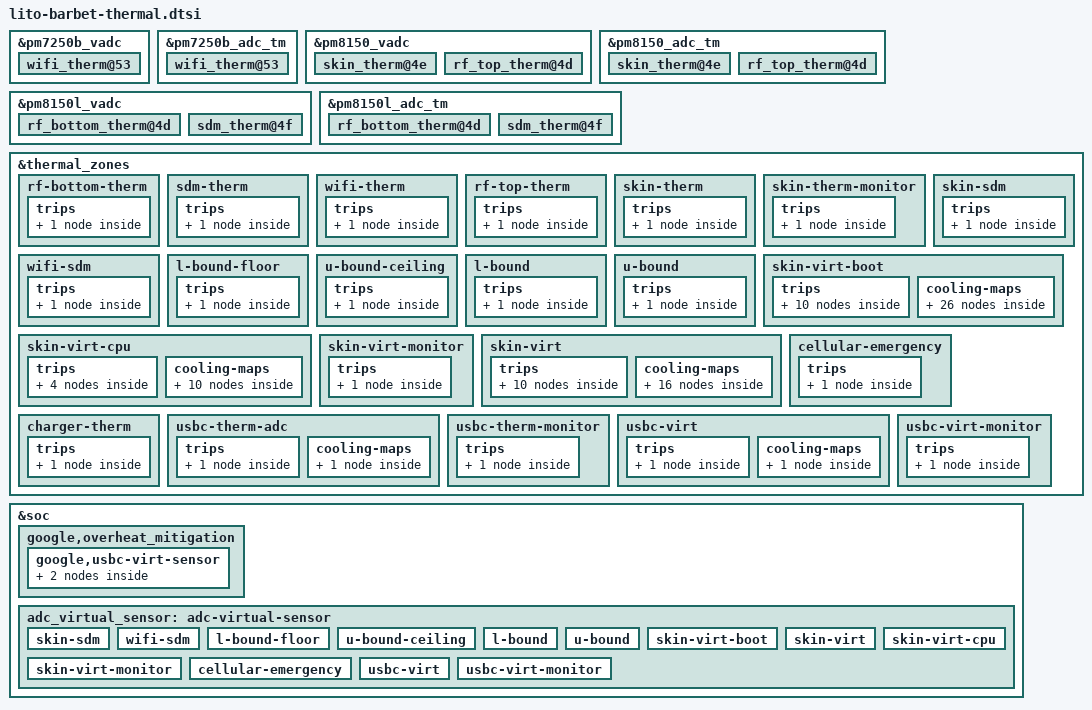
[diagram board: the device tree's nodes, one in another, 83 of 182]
// SPDX-License-Identifier: GPL-2.0
/* Copyright (c) 2019, The Linux Foundation. All rights reserved.
 *
 * This program is free software; you can redistribute it and/or modify
 * it under the terms of the GNU General Public License version 2 and
 * only version 2 as published by the Free Software Foundation.
 *
 * This program is distributed in the hope that it will be useful,
 * but WITHOUT ANY WARRANTY; without even the implied warranty of
 * MERCHANTABILITY or FITNESS FOR A PARTICULAR PURPOSE.  See the
 * GNU General Public License for more details.
 */

&pm7250b_vadc {
	wifi_therm@53 {
		reg = <ADC_GPIO2_PU2>;
		label = "wifi_therm";
		qcom,ratiometric;
		qcom,hw-settle-time = <200>;
		qcom,pre-scaling = <1 1>;
	};
};

&pm7250b_adc_tm {
	io-channels = <&pm7250b_vadc ADC_AMUX_THM1_PU2>,
			<&pm7250b_vadc ADC_AMUX_THM3_PU2>,
			<&pm7250b_vadc ADC_GPIO2_PU2>;

	wifi_therm@53 {
		reg = <ADC_GPIO2_PU2>;
		qcom,ratiometric;
		qcom,hw-settle-time = <200>;
	};
};

&pm8150_vadc {
	skin_therm@4e {
		reg = <ADC_AMUX_THM2_PU2>;
		label = "skin_therm";
		qcom,ratiometric;
		qcom,hw-settle-time = <200>;
		qcom,pre-scaling = <1 1>;
	};

	rf_top_therm@4d {
		reg = <ADC_AMUX_THM1_PU2>;
		label = "rf_top_therm";
		qcom,ratiometric;
		qcom,hw-settle-time = <200>;
		qcom,pre-scaling = <1 1>;
	};
};

&pm8150_adc_tm {
	io-channels = <&pm8150_vadc ADC_XO_THERM_PU2>,
			<&pm8150_vadc ADC_AMUX_THM1_PU2>,
			<&pm8150_vadc ADC_AMUX_THM2_PU2>;

	skin_therm@4e {
		reg = <ADC_AMUX_THM2_PU2>;
		qcom,ratiometric;
		qcom,hw-settle-time = <200>;
	};

	rf_top_therm@4d {
		reg = <ADC_AMUX_THM1_PU2>;
		qcom,ratiometric;
		qcom,hw-settle-time = <200>;
	};
};

&pm8150l_vadc {

	rf_bottom_therm@4d {
		reg = <ADC_AMUX_THM1_PU2>;
		label = "rf_bottom_therm";
		qcom,ratiometric;
		qcom,hw-settle-time = <200>;
		qcom,pre-scaling = <1 1>;
	};

	sdm_therm@4f {
		reg = <ADC_AMUX_THM3_PU2>;
		label = "sdm_therm";
		qcom,ratiometric;
		qcom,hw-settle-time = <200>;
		qcom,pre-scaling = <1 1>;
	};
};

&pm8150l_adc_tm {
	io-channels = <&pm8150l_vadc ADC_AMUX_THM1_PU2>,
			<&pm8150l_vadc ADC_AMUX_THM3_PU2>;

	/* Channel nodes */
	rf_bottom_therm@4d {
		reg = <ADC_AMUX_THM1_PU2>;
		qcom,ratiometric;
		qcom,hw-settle-time = <200>;
	};

	sdm_therm@4f {
		reg = <ADC_AMUX_THM3_PU2>;
		qcom,ratiometric;
		qcom,hw-settle-time = <200>;
	};
};

&thermal_zones {
	rf-bottom-therm {
		polling-delay-passive = <0>;
		polling-delay = <0>;
		thermal-governor = "user_space";
		thermal-sensors = <&pm8150l_adc_tm ADC_AMUX_THM1_PU2>;
		wake-capable-sensor;
		trips {
			active-config0 {
				temperature = <125000>;
				hysteresis = <1000>;
				type = "passive";
			};
		};
	};

	sdm-therm {
		polling-delay-passive = <0>;
		polling-delay = <0>;
		thermal-governor = "user_space";
		thermal-sensors = <&pm8150l_adc_tm ADC_AMUX_THM3_PU2>;
		wake-capable-sensor;
		trips {
			active-config0 {
				temperature = <125000>;
				hysteresis = <1000>;
				type = "passive";
			};
		};
	};

	wifi-therm {
		polling-delay-passive = <0>;
		polling-delay = <0>;
		thermal-governor = "user_space";
		thermal-sensors = <&pm7250b_adc_tm ADC_GPIO2_PU2>;
		wake-capable-sensor;
		trips {
			active-config0 {
				temperature = <125000>;
				hysteresis = <1000>;
				type = "passive";
			};
		};
	};

	rf-top-therm {
		polling-delay-passive = <0>;
		polling-delay = <0>;
		thermal-governor = "user_space";
		thermal-sensors = <&pm8150_adc_tm ADC_AMUX_THM1_PU2>;
		wake-capable-sensor;
		trips {
			active-config0 {
				temperature = <125000>;
				hysteresis = <1000>;
				type = "passive";
			};
		};
	};

	skin-therm {
		polling-delay-passive = <0>;
		polling-delay = <0>;
		thermal-governor = "user_space";
		thermal-sensors = <&pm8150_adc_tm ADC_AMUX_THM2_PU2>;
		wake-capable-sensor;
		trips {
			active-config0 {
				temperature = <125000>;
				hysteresis = <1000>;
				type = "passive";
			};
		};
	};

	skin-therm-monitor {
		polling-delay-passive = <0>;
		polling-delay = <0>;
		thermal-governor = "user_space";
		thermal-sensors = <&pm8150_adc_tm ADC_AMUX_THM2_PU2>;
		wake-capable-sensor;
		trips {
			active-config0 {
				temperature = <125000>;
				hysteresis = <1000>;
				type = "passive";
			};
		};
	};

	skin-sdm {
		polling-delay-passive = <0>;
		polling-delay = <0>;
		thermal-governor = "user_space";
		disable-thermal-zone;
		trips {
			active-config0 {
				temperature = <125000>;
				hysteresis = <1000>;
				type = "passive";
			};
		};
	};

	wifi-sdm {
		polling-delay-passive = <0>;
		polling-delay = <0>;
		thermal-governor = "user_space";
		disable-thermal-zone;
		trips {
			active-config0 {
				temperature = <125000>;
				hysteresis = <1000>;
				type = "passive";
			};
		};
	};

	l-bound-floor {
		polling-delay-passive = <0>;
		polling-delay = <0>;
		thermal-governor = "user_space";
		disable-thermal-zone;
		trips {
			active-config0 {
				temperature = <125000>;
				hysteresis = <1000>;
				type = "passive";
			};
		};
	};

	u-bound-ceiling {
		polling-delay-passive = <0>;
		polling-delay = <0>;
		thermal-governor = "user_space";
		disable-thermal-zone;
		trips {
			active-config0 {
				temperature = <125000>;
				hysteresis = <1000>;
				type = "passive";
			};
		};
	};

	l-bound {
		polling-delay-passive = <0>;
		polling-delay = <0>;
		thermal-governor = "user_space";
		disable-thermal-zone;
		trips {
			active-config0 {
				temperature = <125000>;
				hysteresis = <1000>;
				type = "passive";
			};
		};
	};

	u-bound {
		polling-delay-passive = <0>;
		polling-delay = <0>;
		thermal-governor = "user_space";
		disable-thermal-zone;
		trips {
			active-config0 {
				temperature = <125000>;
				hysteresis = <1000>;
				type = "passive";
			};
		};
	};

	skin-virt-boot {
		polling-delay-passive = <5000>;
		polling-delay = <5000>;
		thermal-governor = "step_wise";
		trips {
			boot_light_pre_lv1: boot-light-pre-lv1 {
				temperature = <41000>;
				hysteresis = <1000>;
				type = "passive";
			};
			boot_light_pre_lv2: boot-light-pre-lv2 {
				temperature = <42000>;
				hysteresis = <1000>;
				type = "passive";
			};
			boot_light: boot-light {
				temperature = <43000>;
				hysteresis = <1000>;
				type = "passive";
			};
			boot_moderate_pre_lv1: boot-moderate-pre-lv1 {
				temperature = <44000>;
				hysteresis = <1000>;
				type = "passive";
			};
			boot_moderate: boot-moderate {
				temperature = <45000>;
				hysteresis = <1000>;
				type = "passive";
			};
			boot_severe_pre_lv1: boot-severe-pre-lv1 {
				temperature = <46000>;
				hysteresis = <1000>;
				type = "passive";
			};
			boot_severe: boot-severe {
				temperature = <47000>;
				hysteresis = <1000>;
				type = "passive";
			};
			boot_critical: boot-critical {
				temperature = <49000>;
				hysteresis = <1000>;
				type = "passive";
			};
			boot_emergency_pre_lv1: boot-emerency-pre-lv1 {
				temperature = <51000>;
				hysteresis = <1000>;
				type = "passive";
			};
			boot_backup_shutdown: boot-backup-shutdown {
				temperature = <59000>;
				hysteresis = <1000>;
				type = "critical";
			};
		};
		cooling-maps {
			/* light pre level 1 throttling */
			wired-charge-pd-5v {
				trip = <&boot_light_pre_lv1>;
				cooling-device = <&google_charger_pd_5v
					THERMAL_MAX_LIMIT THERMAL_MAX_LIMIT>;
			};
			wired-charge-ibat-3000mA {
				trip = <&boot_light_pre_lv1>;
				cooling-device =
					<&google_charger 2 2>;
			};
			/* light pre level 2 throttling */
			wired-charge-ibat-2500mA {
				trip = <&boot_light_pre_lv2>;
				cooling-device =
					<&google_charger 3 3>;
			};
			/* light throttling */
			wired-charge-ibat-2000mA {
				trip = <&boot_light>;
				cooling-device =
					<&google_charger 4 4>;
			};
			cpu6-turbo {
				trip = <&boot_light>;
				cooling-device =
					<&CPU6 1 2>;
			};
			cpu7-turbo {
				trip = <&boot_light>;
				cooling-device =
					<&CPU7 1 1>;
			};
			/* moderate pre level 1 throttling */
			wired-charge-ibat-1500mA {
				trip = <&boot_moderate_pre_lv1>;
				cooling-device =
					<&google_charger 5 5>;
			};
			cpu6-nominal-l1 {
				trip = <&boot_moderate_pre_lv1>;
				cooling-device =
					<&CPU6 3 3>;
			};
			cpu7-nominal-l1 {
				trip = <&boot_moderate_pre_lv1>;
				cooling-device =
					<&CPU7 2 3>;
			};
			/* moderate throttling */
			wired-charge-ibat-1000mA {
				trip = <&boot_moderate>;
				cooling-device =
					<&google_charger 6 6>;
			};
			cpu0-nominal {
				trip = <&boot_moderate>;
				cooling-device =
					<&CPU0 1 3>;
			};
			cpu6-nominal {
				trip = <&boot_moderate>;
				cooling-device =
					<&CPU6 4 4>;
			};
			cpu7-nominal {
				trip = <&boot_moderate>;
				cooling-device =
					<&CPU7 4 4>;
			};
			/* severe pre level 1 throttling */
			wired-charge-ibat-500mA {
				trip = <&boot_severe_pre_lv1>;
				cooling-device =
					<&google_charger 7 7>;
			};
			/* severe throttling */
			wired-charge-disabled {
				trip = <&boot_severe>;
				cooling-device = <&google_charger
					THERMAL_MAX_LIMIT THERMAL_MAX_LIMIT>;
			};
			cpu0-svs-l1 {
				trip = <&boot_severe>;
				cooling-device =
					<&CPU0 4 4>;
			};
			cpu6-svs-l1 {
				trip = <&boot_severe>;
				cooling-device =
					<&CPU6 5 5>;
			};
			cpu7-svs-l1 {
				trip = <&boot_severe>;
				cooling-device =
					<&CPU7 5 5>;
			};
			/* critical throttling */
			gpu-svs-l1 {
				trip = <&boot_critical>;
				cooling-device = <&msm_gpu 1 1>;
			};
			cpu0-svs {
				trip = <&boot_critical>;
				cooling-device =
					<&CPU0 5 5>;
			};
			cpu6-svs {
				trip = <&boot_critical>;
				cooling-device =
					<&CPU6 6 6>;
			};
			cpu7-svs {
				trip = <&boot_critical>;
				cooling-device =
					<&CPU7 6 6>;
			};
			/* emergency pre level 1 throttling */
			gpu-svs {
				trip = <&boot_emergency_pre_lv1>;
				cooling-device =
					<&msm_gpu 2 2>;
			};
			cpu0-low-svs {
				trip = <&boot_emergency_pre_lv1>;
				cooling-device =
					<&CPU0 6 6>;
			};
			cpu6-low-svs {
				trip = <&boot_emergency_pre_lv1>;
				cooling-device =
					<&CPU6 7 7>;
			};
			cpu7-low-svs {
				trip = <&boot_emergency_pre_lv1>;
				cooling-device =
					<&CPU7 7 7>;
			};
		};
	};

	skin-virt-cpu {
		polling-delay-passive = <5000>;
		polling-delay = <10000>;
		thermal-governor = "step_wise";
		disable-thermal-zone;
		trips {
			skin_cpu_light: skin-cpu-light {
				temperature = <43000>;
				hysteresis = <1000>;
				type = "passive";
			};
			skin_cpu_moderate_pre_lv1: skin-cpu-moderate-pre-lv1 {
				temperature = <44000>;
				hysteresis = <1000>;
				type = "passive";
			};
			skin_cpu_moderate: skin-cpu-moderate {
				temperature = <45000>;
				hysteresis = <1000>;
				type = "passive";
			};
			skin_cpu_severe: skin-cpu-severe {
				temperature = <47000>;
				hysteresis = <1000>;
				type = "passive";
			};
		};
		cooling-maps {
			/* light throttling */
			cpu6-turbo {
				trip = <&skin_cpu_light>;
				cooling-device =
					<&CPU6 1 2>;
			};
			cpu7-turbo {
				trip = <&skin_cpu_light>;
				cooling-device =
					<&CPU7 1 1>;
			};
			/* moderate pre level 1 throttling */
			cpu6-nominal-l1 {
				trip = <&skin_cpu_moderate_pre_lv1>;
				cooling-device =
					<&CPU6 3 3>;
			};
			cpu7-nominal-l1 {
				trip = <&skin_cpu_moderate_pre_lv1>;
				cooling-device =
					<&CPU7 2 3>;
			};
			/* moderate throttling */
			cpu0-nominal {
				trip = <&skin_cpu_moderate>;
				cooling-device =
					<&CPU0 1 3>;
			};
			cpu6-nominal {
				trip = <&skin_cpu_moderate>;
				cooling-device =
					<&CPU6 4 4>;
			};
			cpu7-nominal {
				trip = <&skin_cpu_moderate>;
				cooling-device =
					<&CPU7 4 4>;
			};
			/* severe throttling */
			cpu0-svs-l1 {
				trip = <&skin_cpu_severe>;
				cooling-device =
					<&CPU0 4 4>;
			};
			cpu6-svs-l1 {
				trip = <&skin_cpu_severe>;
				cooling-device =
					<&CPU6 5 5>;
			};
			cpu7-svs-l1 {
				trip = <&skin_cpu_severe>;
				cooling-device =
					<&CPU7 5 5>;
			};
		};
	};

	skin-virt-monitor {
		polling-delay-passive = <0>;
		polling-delay = <0>;
		thermal-governor = "user_space";
		trips {
			active-config0 {
				temperature = <125000>;
				hysteresis = <1000>;
				type = "passive";
			};
		};
	};

	skin-virt {
		polling-delay-passive = <5000>;
		polling-delay = <10000>;
		thermal-governor = "step_wise";
		disable-thermal-zone;
		trips {
			skin_light_pre_lv1: skin-light-pre-lv1 {
				temperature = <41000>;
				hysteresis = <1000>;
				type = "passive";
			};
			skin_light_pre_lv2: skin-light-pre-lv2 {
				temperature = <42000>;
				hysteresis = <1000>;
				type = "passive";
			};
			skin_light: skin-light {
				temperature = <43000>;
				hysteresis = <1000>;
				type = "passive";
			};
			skin_moderate_pre_lv1: skin-moderate-pre-lv1 {
				temperature = <44000>;
				hysteresis = <1000>;
				type = "passive";
			};
			skin_moderate: skin-moderate {
				temperature = <45000>;
				hysteresis = <1000>;
				type = "passive";
			};
			skin_severe_pre_lv1: skin-severe-pre-lv1 {
				temperature = <46000>;
				hysteresis = <1000>;
				type = "passive";
			};
			skin_severe: skin-severe {
				temperature = <47000>;
				hysteresis = <1000>;
				type = "passive";
			};
			skin_critical: skin-critical {
				temperature = <49000>;
				hysteresis = <1000>;
				type = "passive";
			};
			skin_emergency_pre_lv1: skin-emerency-pre-lv1 {
				temperature = <51000>;
				hysteresis = <1000>;
				type = "passive";
			};
			skin_backup_shutdown: skin-backup-shutdown {
				temperature = <59000>;
				hysteresis = <1000>;
				type = "critical";
			};
		};
		cooling-maps {
			/* light pre level 1 throttling */
			wired-charge-pd-5v {
				trip = <&skin_light_pre_lv1>;
				cooling-device = <&google_charger_pd_5v
					THERMAL_MAX_LIMIT THERMAL_MAX_LIMIT>;
			};
			wired-charge-ibat-3000mA {
				trip = <&skin_light_pre_lv1>;
				cooling-device =
					<&google_charger 2 2>;
			};
			/* light pre level 2 throttling */
			wired-charge-ibat-2500mA {
				trip = <&skin_light_pre_lv2>;
				cooling-device =
					<&google_charger 3 3>;
			};
			/* light throttling */
			wired-charge-ibat-2000mA {
				trip = <&skin_light>;
				cooling-device =
					<&google_charger 4 4>;
			};
			/* moderate pre level 1 throttling */
			wired-charge-ibat-1500mA {
				trip = <&skin_moderate_pre_lv1>;
				cooling-device =
					<&google_charger 5 5>;
			};
			/* moderate throttling */
			wired-charge-ibat-1000mA {
				trip = <&skin_moderate>;
				cooling-device =
					<&google_charger 6 6>;
			};
			/* severe pre level 1 throttling */
			wired-charge-ibat-500mA {
				trip = <&skin_severe_pre_lv1>;
				cooling-device =
					<&google_charger 7 7>;
			};
			/* severe throttling */
			wired-charge-disabled {
				trip = <&skin_severe>;
				cooling-device = <&google_charger
					THERMAL_MAX_LIMIT THERMAL_MAX_LIMIT>;
			};
			/* critical throttling */
			gpu-svs-l1 {
				trip = <&skin_critical>;
				cooling-device = <&msm_gpu 1 1>;
			};
			cpu0-svs {
				trip = <&skin_critical>;
				cooling-device =
					<&CPU0 5 5>;
			};
			cpu6-svs {
				trip = <&skin_critical>;
				cooling-device =
					<&CPU6 6 6>;
			};
			cpu7-svs {
				trip = <&skin_critical>;
				cooling-device =
					<&CPU7 6 6>;
			};
			/* emergency pre level 1 throttling */
			gpu-svs {
				trip = <&skin_emergency_pre_lv1>;
				cooling-device =
					<&msm_gpu 2 2>;
			};
			cpu0-low-svs {
				trip = <&skin_emergency_pre_lv1>;
				cooling-device =
					<&CPU0 6 6>;
			};
			cpu6-low-svs {
				trip = <&skin_emergency_pre_lv1>;
				cooling-device =
					<&CPU6 7 7>;
			};
			cpu7-low-svs {
				trip = <&skin_emergency_pre_lv1>;
				cooling-device =
					<&CPU7 7 7>;
			};
		};
	};

	cellular-emergency {
		polling-delay-passive = <0>;
		polling-delay = <0>;
		thermal-governor = "user_space";
		trips {
			active-config0 {
				temperature = <125000>;
				hysteresis = <1000>;
				type = "passive";
			};
		};
	};

	charger-therm {
		polling-delay-passive = <0>;
		polling-delay = <0>;
		thermal-governor = "user_space";
		thermal-sensors = <&pm7250b_adc_tm ADC_AMUX_THM1_PU2>;
		wake-capable-sensor;
		trips {
			active-config0 {
				temperature = <125000>;
				hysteresis = <1000>;
				type = "passive";
			};
		};
	};

	usbc-therm-adc {
		polling-delay-passive = <0>;
		polling-delay = <0>;
		thermal-governor = "step_wise";
		thermal-sensors = <&pm7250b_adc_tm ADC_AMUX_THM3_PU2>;
		wake-capable-sensor;
		trips {
			usb_throttling_lv1: usb-throttling_lv1 {
				temperature = <40000>;
				hysteresis = <1000>;
				type = "passive";
			};
		};
		cooling-maps {
			usb_throttling_lv1 {
				trip = <&usb_throttling_lv1>;
				cooling-device =
					<&google_overheat_mitigation 1 1>;
			};
		};
	};

	usbc-therm-monitor {
		polling-delay-passive = <0>;
		polling-delay = <0>;
		thermal-governor = "user_space";
		thermal-sensors = <&pm7250b_adc_tm ADC_AMUX_THM3_PU2>;
		wake-capable-sensor;
		trips {
			active-config0 {
				temperature = <125000>;
				hysteresis = <1000>;
				type = "passive";
			};
		};
	};

	usbc-virt {
		polling-delay-passive = <2000>;
		polling-delay = <2000>;
		thermal-governor = "step_wise";
		disable-thermal-zone;
		trips {
			usb_throttling_max: usb-throttling_max {
				temperature = <7000>;
				hysteresis = <4000>;
				type = "passive";
			};
		};
		cooling-maps {
			usb_throttling_max {
				trip = <&usb_throttling_max>;
				cooling-device =
					<&google_overheat_mitigation
					THERMAL_MAX_LIMIT THERMAL_MAX_LIMIT>;
			};
		};
	};

	usbc-virt-monitor {
		polling-delay-passive = <0>;
		polling-delay = <0>;
		thermal-governor = "user_space";
		disable-thermal-zone;
		trips {
			active-config0 {
				temperature = <125000>;
				hysteresis = <1000>;
				type = "passive";
			};
		};
	};
};

&soc {
	google,overheat_mitigation {
		google,begin-mitigation-temp = <400>;
		google,end-mitigation-temp = <390>;
		google,usbc-virt-sensor {
			usbc-virt {
				sensor-name = "usbc-virt";
			};

			usbc-virt-monitor {
				sensor-name = "usbc-virt-monitor";
				support_uevent;
			};
		};
	};

	adc_virtual_sensor: adc-virtual-sensor {
	};
};

&adc_virtual_sensor {
	skin-sdm {
		logic = "weight";
		num_sensors = <2>;
		sensor-names = "skin-therm", "sdm-therm";
		coefficients = <1 1>;
		avg-offset = <0>;
		avg-denominator = <2>;
	};

	wifi-sdm {
		logic = "weight";
		num_sensors = <2>;
		sensor-names = "wifi-therm", "sdm-therm";
		coefficients = <28 (-28)>;
		avg-offset = <0>;
		avg-denominator = <100>;
	};

	l-bound-floor {
		logic = "weight";
		num_sensors = <1>;
		sensor-names = "skin-sdm";
		coefficients = <1>;
		avg-offset = <0>;
		avg-denominator = <1>;
	};

	u-bound-ceiling {
		logic = "weight";
		num_sensors = <1>;
		sensor-names = "skin-sdm";
		coefficients = <1>;
		avg-offset = <0>;
		avg-denominator = <1>;
	};

	l-bound {
		logic = "maximum";
		num_sensors = <2>;
		sensor-names = "wifi-sdm", "l-bound-floor";
	};

	u-bound {
		logic = "minimum";
		num_sensors = <2>;
		sensor-names = "l-bound", "u-bound-ceiling";
	};

	skin-virt-boot {
		logic = "weight";
		num_sensors = <2>;
		sensor-names = "skin-therm", "sdm-therm";
		coefficients = <1 1>;
		avg-offset = <0>;
		avg-denominator = <2>;
	};

	skin-virt {
		logic = "weight";
		num_sensors = <2>;
		sensor-names = "skin-sdm", "u-bound";
		coefficients = <1 (-1)>;
		avg-offset = <0>;
		avg-denominator = <1>;
	};

	skin-virt-cpu {
		logic = "weight";
		num_sensors = <2>;
		sensor-names = "skin-sdm", "u-bound";
		coefficients = <1 (-1)>;
		avg-offset = <0>;
		avg-denominator = <1>;
	};

	skin-virt-monitor {
		logic = "weight";
		num_sensors = <2>;
		sensor-names = "skin-sdm", "u-bound";
		coefficients = <1 (-1)>;
		avg-offset = <0>;
		avg-denominator = <1>;
	};

	cellular-emergency {
		logic = "weight";
		num_sensors = <2>;
		sensor-names = "skin-sdm", "u-bound";
		coefficients = <1 (-1)>;
		avg-offset = <0>;
		avg-denominator = <1>;
	};

	usbc-virt {
		logic = "weight";
		num_sensors = <2>;
		sensor-names = "usbc-therm-adc", "charger-therm";
		coefficients = <1 (-1)>;
		avg-offset = <0>;
		avg-denominator = <1>;
	};

	usbc-virt-monitor {
		logic = "weight";
		num_sensors = <2>;
		sensor-names = "usbc-therm-adc", "charger-therm";
		coefficients = <1 (-1)>;
		avg-offset = <0>;
		avg-denominator = <1>;
	};
};
